# STM32N647 register map
File version: 1.0
CPU: CM55 r0p1, little endian, no MPU, FPU, vendor SysTick, 8 interrupt priority bits
Registers are 32-bit, read-write, reset 0x0 unless marked. A register's access mark holds for its fields unless they carry their own. Offsets are from the block's base; [hi:lo] are bit positions; 'fields as' and 'values as' point back to an identical list.

## DTS — Digital temperature sensor
Base 0x4600A000
Same registers: DTS_S 0x5600A000
0x10 PVTREG_LOCKR — DTS PVT register lock register
  [31:0] LOCK — PVT software lock register
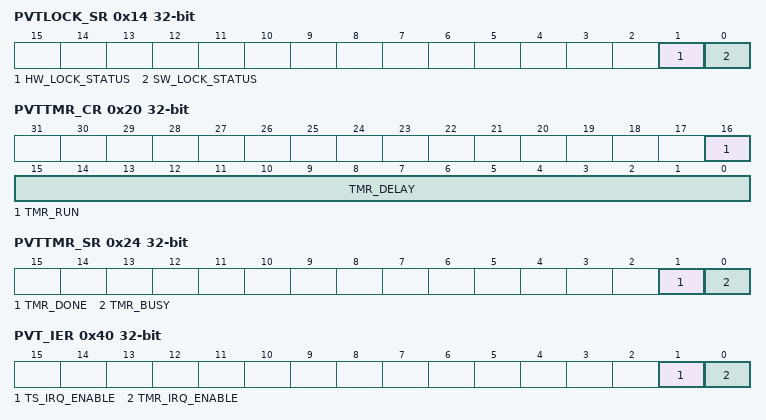
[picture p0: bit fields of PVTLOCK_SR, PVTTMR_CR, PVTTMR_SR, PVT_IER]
0x14 PVTLOCK_SR ro — DTS PVT lock status register
  [1] HW_LOCK_STATUS — Hardware lock input status
  [0] SW_LOCK_STATUS — Software lock input status
0x20 PVTTMR_CR — DTS PVT timer control register
  [16] TMR_RUN — Timer count enable bit
  [15:0] TMR_DELAY — Timer delay
0x24 PVTTMR_SR ro — DTS PVT timer status register
  [1] TMR_DONE — Counter delay expiration flag
  [0] TMR_BUSY — Counter busy flag
0x40 PVT_IER — DTS PVT IRQ enable register
  [1] TS_IRQ_ENABLE — TS IRQ source enable bit
  [0] TMR_IRQ_ENABLE — Timer IRQ source enable bit
0x50 PVTIRQTRMASKR — DTS PVT IRQ timer mask register
  [0] TMR_IRQ_MASK — Timer IRQ source mask bit
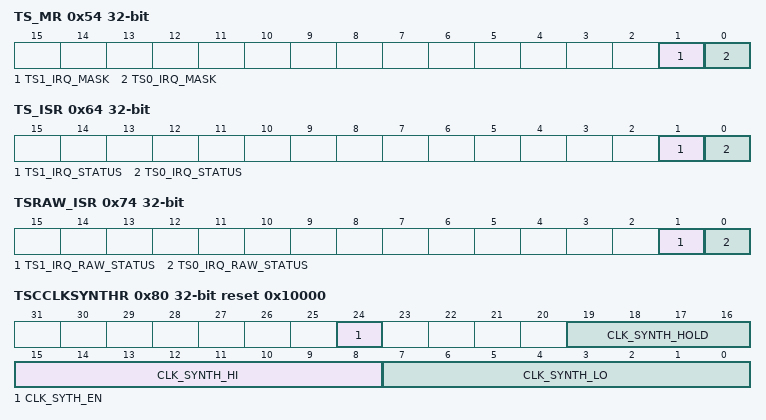
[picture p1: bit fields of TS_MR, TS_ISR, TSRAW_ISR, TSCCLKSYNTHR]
0x54 TS_MR — DTS PVT IRQ TS mask register
  [1] TS1_IRQ_MASK — TS1 IRQ source mask bit
  [0] TS0_IRQ_MASK — TS0 IRQ source mask bit
0x60 PVTTR_SR ro — DTS PVT IRQ timer status register
  [0] TMR_IRQ_STATUS — Timer IRQ status bit after masking
0x64 TS_ISR ro — DTS PVT IRQ TS status register
  [1] TS1_IRQ_STATUS — TS1 IRQ status bit after masking
  [0] TS0_IRQ_STATUS — TS0 IRQ status bit after masking
0x70 PVTTMRRAW_ISR ro — DTS PVT IRQ timer raw status register
  [0] TMR_IRQ_RAW_STATUS — TMR IRQ status bit before masking
0x74 TSRAW_ISR ro — DTS PVT IRQ TS raw status register
  [1] TS1_IRQ_RAW_STATUS — TS1 IRQ status bit before masking
  [0] TS0_IRQ_RAW_STATUS — TS0 IRQ status bit before masking
0x80 TSCCLKSYNTHR reset 0x10000 — DTS TSC clock synthesizer register
  [24] CLK_SYTH_EN — Synthesized clk_ts enable bit
  [19:16] CLK_SYNTH_HOLD — SDA master-to-SDA slave output hold delay/SDA slave-to-SDA master input setup delay
  [15:8] CLK_SYNTH_HI — Synthesized clk_ts high period
  [7:0] CLK_SYNTH_LO — Synthesized clk_ts low period
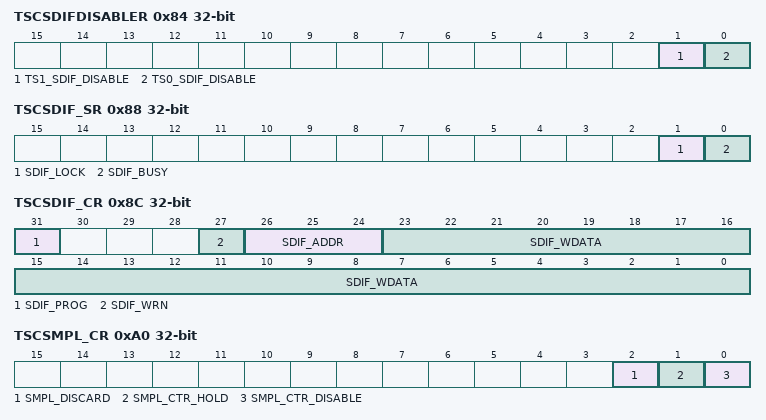
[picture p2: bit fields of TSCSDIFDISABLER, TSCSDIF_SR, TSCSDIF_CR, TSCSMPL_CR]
0x84 TSCSDIFDISABLER — DTS TSC SDIF interface disable register
  [1] TS1_SDIF_DISABLE — TS1 serial data interface (SDIF) disable bit
  [0] TS0_SDIF_DISABLE — TS0 serial data interface (SDIF) disable bit
0x88 TSCSDIF_SR ro — DTS TSC SDIF status register
  [1] SDIF_LOCK — SDIF locked flag
  [0] SDIF_BUSY — SDIF busy flag
0x8C TSCSDIF_CR access per field — DTS TSC SDIF register
  [31] SDIF_PROG wo — Serial interface program request
  [27] SDIF_WRN rw — Serial interface write/no read control bit
  [26:24] SDIF_ADDR rw — Serial interface register address
  [23:0] SDIF_WDATA rw — Serial interface write data
0x90 TSCSDIFHALTR wo — DTS TSC SDIF halt register
  [0] SDIF_STOP — Serial data interface (SDIF) stop
0x94 TSCSDIF_CFGR — DTS TSC SDIF control register
  [1:0] SDIF_INHIBIT — Serial data interface (SDIF) programming inhibit
0xA0 TSCSMPL_CR — DTS TSC sample control register
  [2] SMPL_DISCARD — Sample discard bit
  [1] SMPL_CTR_HOLD — Sample counter hold bit
  [0] SMPL_CTR_DISABLE — Sample counter disable bit
0xA4 TSCSDIFSMPLCLRR wo — DTS TSC sample clear register
  [0] SMPL_CNTER_CLEAR — Sample counter clear bit
0xA8 TSCSMPLCNTR ro — DTS TSC sample count register
  [15:0] SMPL_COUNT — Sample counter
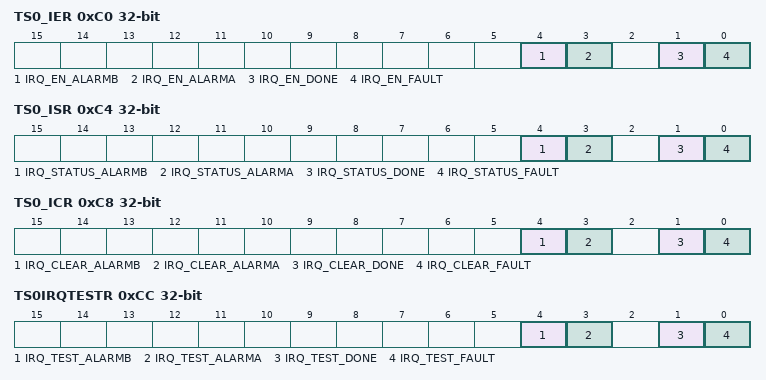
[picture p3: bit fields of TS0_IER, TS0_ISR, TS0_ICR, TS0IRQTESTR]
0xC0 TS0_IER — DTS TS0 IRQ enable register
  [4] IRQ_EN_ALARMB — Alarm B IRQ enable bit
  [3] IRQ_EN_ALARMA — Alarm A IRQ enable bit
  [1] IRQ_EN_DONE — Sample done IRQ enable bit
  [0] IRQ_EN_FAULT — Fault IRQ enable bit
0xC4 TS0_ISR ro — DTS TS0 IRQ status register
  [4] IRQ_STATUS_ALARMB — Alarm B IRQ status bit
  [3] IRQ_STATUS_ALARMA — Alarm A IRQ status bit
  [1] IRQ_STATUS_DONE — Sample done IRQ status bit
  [0] IRQ_STATUS_FAULT — Fault IRQ status bit
0xC8 TS0_ICR wo — DTS TS0 IRQ clear register
  [4] IRQ_CLEAR_ALARMB — Alarm B IRQ clear bit
  [3] IRQ_CLEAR_ALARMA — Alarm A IRQ clear bit
  [1] IRQ_CLEAR_DONE — Sample done IRQ clear bit
  [0] IRQ_CLEAR_FAULT — Fault IRQ clear bit
0xCC TS0IRQTESTR — DTS TS0 IRQ test register
  [4] IRQ_TEST_ALARMB — Alarm B IRQ test bit
  [3] IRQ_TEST_ALARMA — Alarm A IRQ test bit
  [1] IRQ_TEST_DONE — Sample done IRQ test bit
  [0] IRQ_TEST_FAULT — Fault IRQ test bit
0xD0 TS0SDIFRDATAR ro — DTS TS0 SDIF RDATA register
  [23:0] SDIF_RDATA — SDIF read data
0xD4 TS0SDIFDONER ro — DTS TS0 SDIF done register
  [0] SDIF_SMPL_DONE — Sample done flag
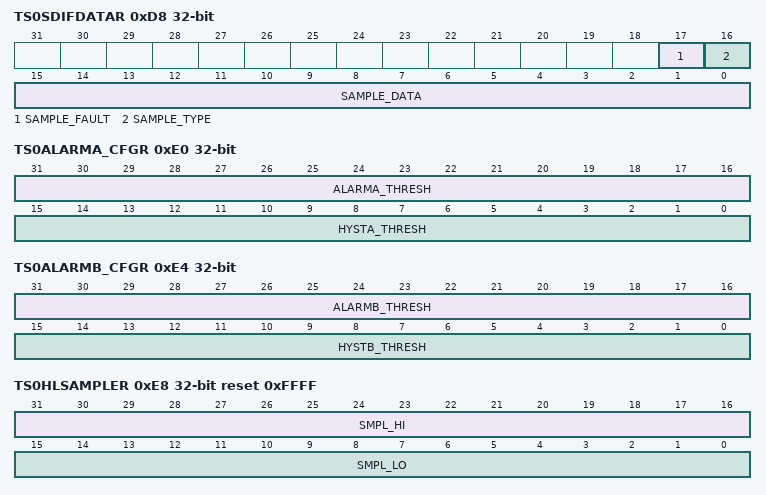
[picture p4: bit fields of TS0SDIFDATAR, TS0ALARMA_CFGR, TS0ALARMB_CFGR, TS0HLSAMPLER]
0xD8 TS0SDIFDATAR ro — DTS TS0 SDIF data register
  [17] SAMPLE_FAULT
  [16] SAMPLE_TYPE — TS sample type
  [15:0] SAMPLE_DATA
0xE0 TS0ALARMA_CFGR — DTS TS0 alarm A configuration register
  [31:16] ALARMA_THRESH — Alarm A threshold
  [15:0] HYSTA_THRESH — Alarm A hysteresis threshold
0xE4 TS0ALARMB_CFGR — DTS TS0 alarm B configuration register
  [31:16] ALARMB_THRESH — Alarm B threshold
  [15:0] HYSTB_THRESH — Alarm B hysteresis threshold
0xE8 TS0HLSAMPLER ro reset 0xFFFF — DTS TS0 high/low sample register
  [31:16] SMPL_HI — Highest valid data sample value received
  [15:0] SMPL_LO — Lowest valid data sample value received
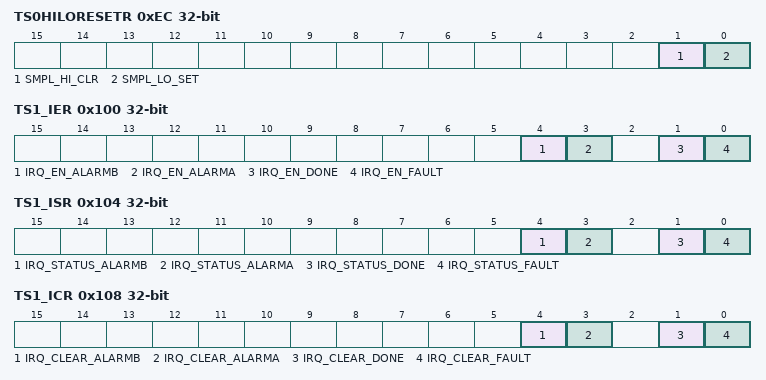
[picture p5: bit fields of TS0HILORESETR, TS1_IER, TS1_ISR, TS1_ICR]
0xEC TS0HILORESETR wo — DTS TS0 high/low reset register
  [1] SMPL_HI_CLR — Sample high clear 0
  [0] SMPL_LO_SET — Sample Low Set
0x100 TS1_IER — DTS TS1 IRQ enable register
  fields as TS0_IER
0x104 TS1_ISR ro — DTS TS1 IRQ status register
  fields as TS0_ISR
0x108 TS1_ICR wo — DTS TS1 IRQ clear register
  fields as TS0_ICR
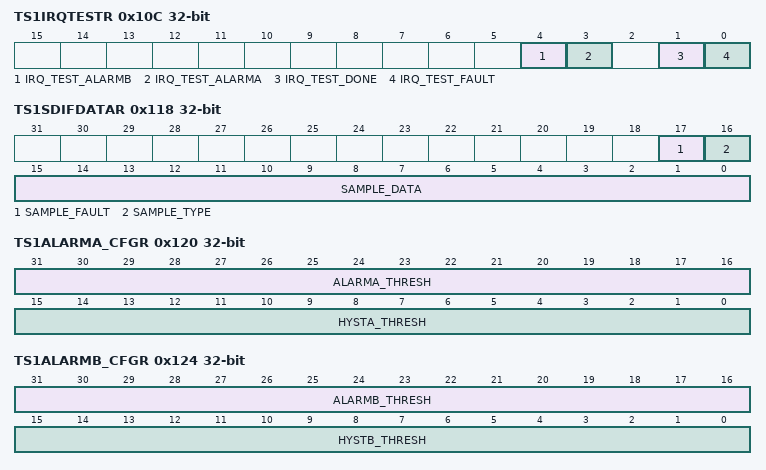
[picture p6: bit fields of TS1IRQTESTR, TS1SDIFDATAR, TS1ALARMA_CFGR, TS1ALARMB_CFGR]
0x10C TS1IRQTESTR — DTS TS1 IRQ test register
  fields as TS0IRQTESTR
0x110 TS1SDIFRDATAR ro — DTS TS1 SDIF RDATA register
  [23:0] SDIF_RDATA — SDIF read data
0x114 TS1SDIFDONER ro — DTS TS1 SDIF done register
  [0] SDIF_SMPL_DONE — Sample done flag
0x118 TS1SDIFDATAR ro — DTS TS1 SDIF data register
  fields as TS0SDIFDATAR
0x120 TS1ALARMA_CFGR — DTS TS1 alarm A configuration register
  fields as TS0ALARMA_CFGR
0x124 TS1ALARMB_CFGR — DTS TS1 alarm B configuration register
  fields as TS0ALARMB_CFGR
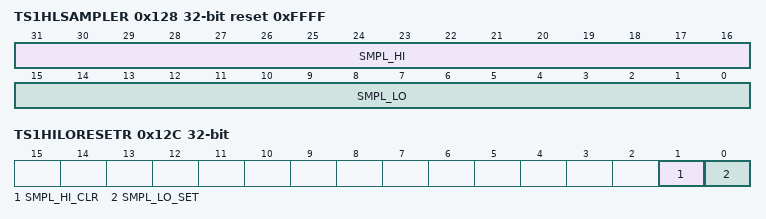
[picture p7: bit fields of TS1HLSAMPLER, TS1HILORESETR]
0x128 TS1HLSAMPLER ro reset 0xFFFF — DTS TS1 high/low sample register
  fields as TS0HLSAMPLER
0x12C TS1HILORESETR wo — DTS TS1 high/low reset register
  fields as TS0HILORESETR
